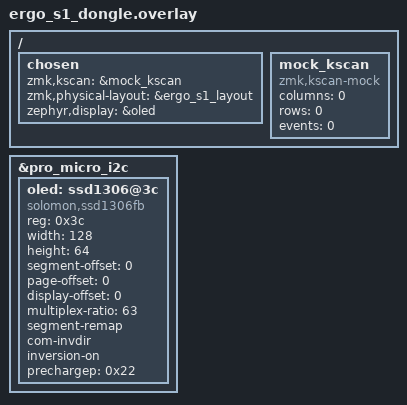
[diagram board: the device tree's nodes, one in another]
/*
 * Ergo S1 dongle — a bare nice!nano v2 acting as split central.
 * Both halves connect to it as peripherals. No keys of its own (mock kscan).
 * Carries the full physical layout so ZMK Studio can show and edit the keymap.
 *
 * OLED: 0.96" SSD1306 128x64 on I2C (address 0x3C)
 *   SDA -> pro_micro D2 (P0.17)   SCL -> pro_micro D3 (P0.20)
 *   VCC -> 3V3 (VCC pin)          GND -> GND
 * For a 0.91" 128x32 panel instead: height = <32>, multiplex-ratio = <31>, and add com-sequential.
 */

#include "ergo_s1-layouts.dtsi"

/ {
    chosen {
        zmk,kscan = &mock_kscan;
        zmk,physical-layout = &ergo_s1_layout;
        zephyr,display = &oled;
    };

    mock_kscan: mock_kscan {
        compatible = "zmk,kscan-mock";
        columns = <0>;
        rows = <0>;
        events = <0>;
    };
};

&pro_micro_i2c {
    status = "okay";

    oled: ssd1306@3c {
        compatible = "solomon,ssd1306fb";
        reg = <0x3c>;
        width = <128>;
        height = <64>;
        segment-offset = <0>;
        page-offset = <0>;
        display-offset = <0>;
        multiplex-ratio = <63>;
        segment-remap;
        com-invdir;
        inversion-on;
        prechargep = <0x22>;
    };
};
